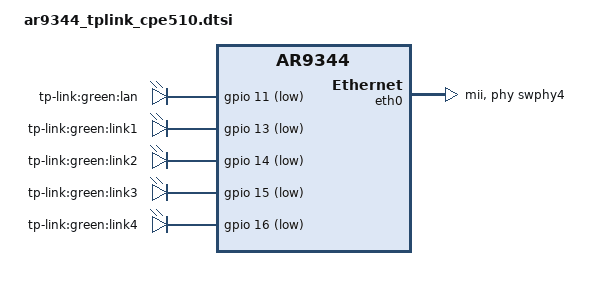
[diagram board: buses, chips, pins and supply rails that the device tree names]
// SPDX-License-Identifier: GPL-2.0-or-later OR MIT
/dts-v1/;

#include "ar9344_tplink_cpexxx.dtsi"

/ {
	aliases {
		led-boot = &system;
		led-failsafe = &system;
		led-running = &system;
		led-upgrade = &system;
	};

	leds {
		compatible = "gpio-leds";

		lan {
			label = "tp-link:green:lan";
			gpios = <&gpio 11 GPIO_ACTIVE_LOW>;
		};

		link1 {
			label = "tp-link:green:link1";
			gpios = <&gpio 13 GPIO_ACTIVE_LOW>;
		};

		link2 {
			label = "tp-link:green:link2";
			gpios = <&gpio 14 GPIO_ACTIVE_LOW>;
		};

		link3 {
			label = "tp-link:green:link3";
			gpios = <&gpio 15 GPIO_ACTIVE_LOW>;
		};

		system: link4 {
			label = "tp-link:green:link4";
			gpios = <&gpio 16 GPIO_ACTIVE_LOW>;
		};
	};
};

&eth0 {
	status = "okay";

	mtd-mac-address = <&info 0x08>;

	phy-mode = "mii";
	phy-handle = <&swphy4>;
};

&eth1 {
	status = "okay";
	compatible = "syscon", "simple-mfd";
};
